# CY8C5888LTI_LP097 register map
File version: 0.1
Registers are 8-bit, read-write, no defined reset value unless marked. A register's access mark holds for its fields unless they carry their own. Offsets are from the block's base; [hi:lo] are bit positions; 'fields as' and 'values as' point back to an identical list.

## Handle_Encoder
Base 0x00000000
0x40006400 Handle_Encoder_Cnt16_COUNTER 16-bit — Counter value
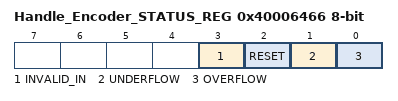
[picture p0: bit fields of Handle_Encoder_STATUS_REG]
0x40006466 Handle_Encoder_STATUS_REG — Quadrature Decoder Status Register
  [3] INVALID_IN ro — Invalid state transition on the A and B inputs
  [2] RESET ro — Counter Reset due index
  [1] UNDERFLOW ro — Counter underflow
  [0] OVERFLOW ro — Counter overflow

## Handle_Encoder_Cnt16
Base 0x00000000; alternate view of Handle_Encoder
0x40006400 Handle_Encoder_Cnt16_COUNTER 16-bit — UDB.A0 - Current Counter Value
0x40006420 Handle_Encoder_Cnt16_PERIOD 16-bit — UDB.D0 - Assigned Period
0x40006430 Handle_Encoder_Cnt16_COMPARE 16-bit — UDB.D1 - Assigned Compare Value
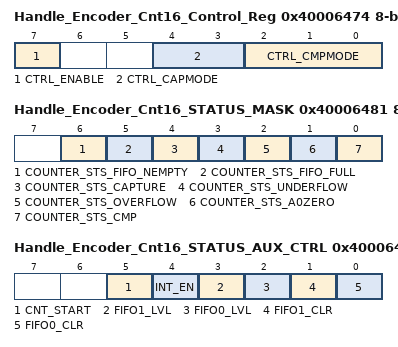
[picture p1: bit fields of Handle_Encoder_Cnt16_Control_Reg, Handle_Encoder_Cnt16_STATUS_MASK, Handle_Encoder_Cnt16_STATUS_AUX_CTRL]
0x40006474 Handle_Encoder_Cnt16_Control_Reg — UDB Control Register - Assigned Control Register Value
  [7] CTRL_ENABLE — Enable Counter
  [4:3] CTRL_CAPMODE — Capture mode
  [2:0] CTRL_CMPMODE — Compare mode
0x40006481 Handle_Encoder_Cnt16_STATUS_MASK — UDB Status bits Interrupt Mask Enable Register
  [6] COUNTER_STS_FIFO_NEMPTY — FIFO Not Empty Status
  [5] COUNTER_STS_FIFO_FULL — FIFO Full Status
  [4] COUNTER_STS_CAPTURE — Capture Status
  [3] COUNTER_STS_UNDERFLOW — Underflow status
  [2] COUNTER_STS_OVERFLOW — Overflow status
  [1] COUNTER_STS_A0ZERO — A0 Zero ouput status
  [0] COUNTER_STS_CMP — Compare output status
0x40006491 Handle_Encoder_Cnt16_STATUS_AUX_CTRL — UDB Auxilliary Control Register
  [5] CNT_START — FIFO0 clear
    0=E_CNT_START0 (Disable counter); 1=E_CNT_START1 (Enable counter)
  [4] INT_EN
    0=E_INT_EN0 (Interrupt disabled); 1=E_INT_EN1 (Interrupt enabled)
  [3] FIFO1_LVL — FIFO level
    0=E_FIFO_LVL_0 (FIFO LVL: input mode: FIFO not full; output mode: FIFO not empty); 1=E_FIFO_LVL_1 (FIFO LVL: input mode: FIFO at least 1/2 empty; output mode: FIFO at least 1/2 full)
  [2] FIFO0_LVL — FIFO level
    values as FIFO1_LVL
  [1] FIFO1_CLR — FIFO1 clear
    0=E_FIFO_CLR_0 (Normal FIFO operation); 1=E_FIFO_CLR_1 (Clear FIFO state)
  [0] FIFO0_CLR — FIFO0 clear
    values as FIFO1_CLR

## Gimbal_Encoder
Base 0x00000000
0x40006408 Gimbal_Encoder_Cnt16_COUNTER 16-bit — Counter value
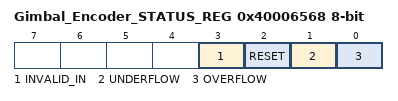
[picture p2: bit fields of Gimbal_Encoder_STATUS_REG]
0x40006568 Gimbal_Encoder_STATUS_REG — Quadrature Decoder Status Register
  [3] INVALID_IN ro — Invalid state transition on the A and B inputs
  [2] RESET ro — Counter Reset due index
  [1] UNDERFLOW ro — Counter underflow
  [0] OVERFLOW ro — Counter overflow

## Gimbal_Encoder_Cnt16
Base 0x00000000; alternate view of Gimbal_Encoder
0x40006408 Gimbal_Encoder_Cnt16_COUNTER 16-bit — UDB.A0 - Current Counter Value
0x40006428 Gimbal_Encoder_Cnt16_PERIOD 16-bit — UDB.D0 - Assigned Period
0x40006438 Gimbal_Encoder_Cnt16_COMPARE 16-bit — UDB.D1 - Assigned Compare Value
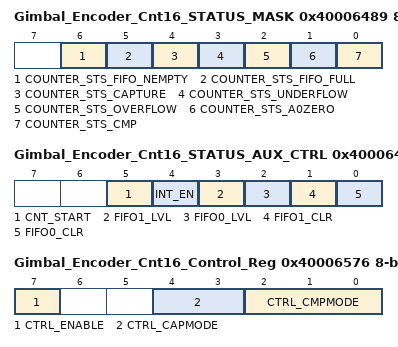
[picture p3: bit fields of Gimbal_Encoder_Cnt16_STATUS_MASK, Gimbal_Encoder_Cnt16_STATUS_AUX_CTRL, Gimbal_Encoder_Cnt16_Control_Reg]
0x40006489 Gimbal_Encoder_Cnt16_STATUS_MASK — UDB Status bits Interrupt Mask Enable Register
  [6] COUNTER_STS_FIFO_NEMPTY — FIFO Not Empty Status
  [5] COUNTER_STS_FIFO_FULL — FIFO Full Status
  [4] COUNTER_STS_CAPTURE — Capture Status
  [3] COUNTER_STS_UNDERFLOW — Underflow status
  [2] COUNTER_STS_OVERFLOW — Overflow status
  [1] COUNTER_STS_A0ZERO — A0 Zero ouput status
  [0] COUNTER_STS_CMP — Compare output status
0x40006499 Gimbal_Encoder_Cnt16_STATUS_AUX_CTRL — UDB Auxilliary Control Register
  [5] CNT_START — FIFO0 clear
    0=E_CNT_START0 (Disable counter); 1=E_CNT_START1 (Enable counter)
  [4] INT_EN
    0=E_INT_EN0 (Interrupt disabled); 1=E_INT_EN1 (Interrupt enabled)
  [3] FIFO1_LVL — FIFO level
    0=E_FIFO_LVL_0 (FIFO LVL: input mode: FIFO not full; output mode: FIFO not empty); 1=E_FIFO_LVL_1 (FIFO LVL: input mode: FIFO at least 1/2 empty; output mode: FIFO at least 1/2 full)
  [2] FIFO0_LVL — FIFO level
    values as FIFO1_LVL
  [1] FIFO1_CLR — FIFO1 clear
    0=E_FIFO_CLR_0 (Normal FIFO operation); 1=E_FIFO_CLR_1 (Clear FIFO state)
  [0] FIFO0_CLR — FIFO0 clear
    values as FIFO1_CLR
0x40006576 Gimbal_Encoder_Cnt16_Control_Reg — UDB Control Register - Assigned Control Register Value
  [7] CTRL_ENABLE — Enable Counter
  [4:3] CTRL_CAPMODE — Capture mode
  [2:0] CTRL_CMPMODE — Compare mode

## PWM_CMG
Base 0x00000000
0x40006425 PWM_CMG_COMPARE_1 16-bit — UDB.D0 - Assigned Compare1 Value
0x40006435 PWM_CMG_COMPARE_2 16-bit — UDB.D1 - Assigned Compare2 Value
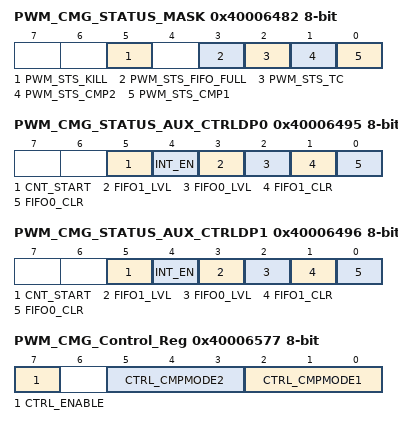
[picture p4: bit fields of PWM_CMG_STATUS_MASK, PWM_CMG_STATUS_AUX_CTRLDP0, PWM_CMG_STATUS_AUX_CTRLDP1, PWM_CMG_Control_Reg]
0x40006482 PWM_CMG_STATUS_MASK — UDB Status bits Interrupt Mask Enable Register
  [5] PWM_STS_KILL ro — Enables the Interrupt on Kill
  [3] PWM_STS_FIFO_FULL ro — FIFO Full Status Mask
  [2] PWM_STS_TC ro — Enables the Interrupt on Terminal Count
  [1] PWM_STS_CMP2 ro — Enables the Interrupt on Compare 2
  [0] PWM_STS_CMP1 ro — Enables the Interrupt on Compare 1
0x40006495 PWM_CMG_STATUS_AUX_CTRLDP0 — UDB Auxilliary Control Register
  [5] CNT_START — FIFO0 clear
    0=E_CNT_START0 (Disable counter); 1=E_CNT_START1 (Enable counter)
  [4] INT_EN
    0=E_INT_EN0 (Interrupt disabled); 1=E_INT_EN1 (Interrupt enabled)
  [3] FIFO1_LVL — FIFO level
    0=E_FIFO_LVL_0 (FIFO LVL: input mode: FIFO not full; output mode: FIFO not empty); 1=E_FIFO_LVL_1 (FIFO LVL: input mode: FIFO at least 1/2 empty; output mode: FIFO at least 1/2 full)
  [2] FIFO0_LVL — FIFO level
    values as FIFO1_LVL
  [1] FIFO1_CLR — FIFO1 clear
    0=E_FIFO_CLR_0 (Normal FIFO operation); 1=E_FIFO_CLR_1 (Clear FIFO state)
  [0] FIFO0_CLR — FIFO0 clear
    values as FIFO1_CLR
0x40006496 PWM_CMG_STATUS_AUX_CTRLDP1 — UDB Auxilliary Control Register
  fields as PWM_CMG_STATUS_AUX_CTRLDP0
0x40006577 PWM_CMG_Control_Reg — UDB Control Register - Assigned Control Register Value
  [7] CTRL_ENABLE — Enable the PWM
  [5:3] CTRL_CMPMODE2 — Compare mode 2
  [2:0] CTRL_CMPMODE1 — Compare mode 1

## UART
Base 0x00000000
0x40006447 TX_UART_TX_DATA — TX Data Register
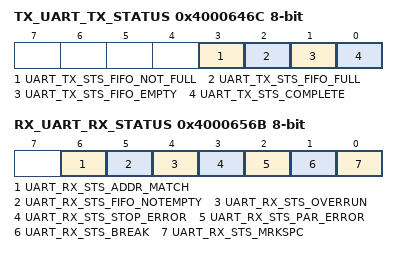
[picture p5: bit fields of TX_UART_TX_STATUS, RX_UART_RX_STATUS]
0x4000646C TX_UART_TX_STATUS — TX status register
  [3] UART_TX_STS_FIFO_NOT_FULL ro, [2] UART_TX_STS_FIFO_FULL ro, [1] UART_TX_STS_FIFO_EMPTY ro, [0] UART_TX_STS_COMPLETE ro
0x40006527 RX_UART_RX_ADDRESS1 — RX Address1 Register
0x40006537 RX_UART_RX_ADDRESS2 — RX Address2 Register
0x40006547 RX_UART_RX_DATA — RX Data Register
0x4000656B RX_UART_RX_STATUS — RX status register
  [6] UART_RX_STS_ADDR_MATCH ro, [5] UART_RX_STS_FIFO_NOTEMPTY ro, [4] UART_RX_STS_OVERRUN ro, [3] UART_RX_STS_STOP_ERROR ro, [2] UART_RX_STS_PAR_ERROR ro, [1] UART_RX_STS_BREAK ro, [0] UART_RX_STS_MRKSPC ro
